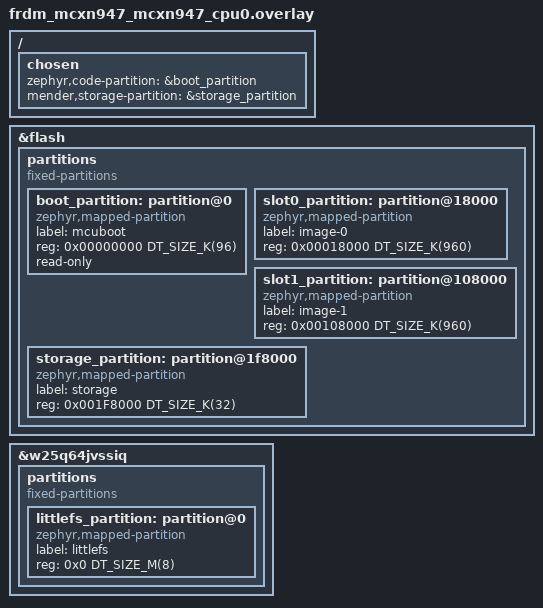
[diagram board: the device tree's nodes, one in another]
/**
 * @file      frdm_mcxn947_mcxn947_cpu0.overlay
 * @brief     frdm-mcxn947 board mcuboot overlay
 *
 * Copyright joelguittet and mender-mcu-client contributors
 *
 * Licensed under the Apache License, Version 2.0 (the "License");
 * you may not use this file except in compliance with the License.
 * You may obtain a copy of the License at
 *
 *     http://www.apache.org/licenses/LICENSE-2.0
 *
 * Unless required by applicable law or agreed to in writing, software
 * distributed under the License is distributed on an "AS IS" BASIS,
 * WITHOUT WARRANTIES OR CONDITIONS OF ANY KIND, either express or implied.
 * See the License for the specific language governing permissions and
 * limitations under the License.
 */

/delete-node/ &boot_partition;
/delete-node/ &slot0_partition;
/delete-node/ &slot1_partition;
/delete-node/ &storage_partition;

/ {
    chosen {
        zephyr,code-partition = &boot_partition;
        mender,storage-partition = &storage_partition;
    };
};

&flash {
    status = "okay";
    partitions {
        compatible = "fixed-partitions";
        #address-cells = <1>;
        #size-cells = <1>;
        /* Bootloader slot: 96KB */
        boot_partition: partition@0 {
            compatible = "zephyr,mapped-partition";
            label = "mcuboot";
            reg = <0x00000000 DT_SIZE_K(96)>;
            read-only;
        };
        /* Application slot: 960KB */
        slot0_partition: partition@18000 {
            compatible = "zephyr,mapped-partition";
            label = "image-0";
            reg = <0x00018000 DT_SIZE_K(960)>;
        };
        /* Update slot: 960KB */
        slot1_partition: partition@108000 {
            compatible = "zephyr,mapped-partition";
            label = "image-1";
            reg = <0x00108000 DT_SIZE_K(960)>;
        };
        /* Storage slot: 32KB */
        storage_partition: partition@1f8000 {
            compatible = "zephyr,mapped-partition";
            label = "storage";
            reg = <0x001F8000 DT_SIZE_K(32)>;
        };
    };
};

&w25q64jvssiq {
    status = "okay";
    partitions {
        compatible = "fixed-partitions";
        #address-cells = <1>;
        #size-cells = <1>;
        littlefs_partition: partition@0 {
            compatible = "zephyr,mapped-partition";
            label = "littlefs";
            reg = <0x0 DT_SIZE_M(8)>;
        };
    };
};
